# TestDevice register map
Vendor: TestVendor; Series: TestSeries; File version: 1.0
Test device for svdtoheaders.
CPU: CM4 r0p1, little endian, no MPU, FPU, 4 interrupt priority bits
Registers are 32-bit, read-write, reset 0x0 unless marked. A register's access mark holds for its fields unless they carry their own. Offsets are from the block's base; lines under a group give offsets from that group; [hi:lo] are bit positions; {n}, {i} and the like mark numbered series; 'fields as' and 'values as' point back to an identical list; <NAME> marks a mode.

## Memory map
0x40001000 TEST_PERIPH size 0x100 — A test peripheral.
0x40002000 DERIVED_PERIPH size 0x100 — A test derived peripheral.

## TEST_PERIPH — A test peripheral.
Base 0x40001000
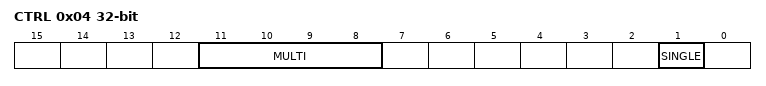
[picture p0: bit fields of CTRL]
0x04 CTRL — Control Register
  [11:8] MULTI — A multi-bit field.
  [1] SINGLE — A single bit field.
